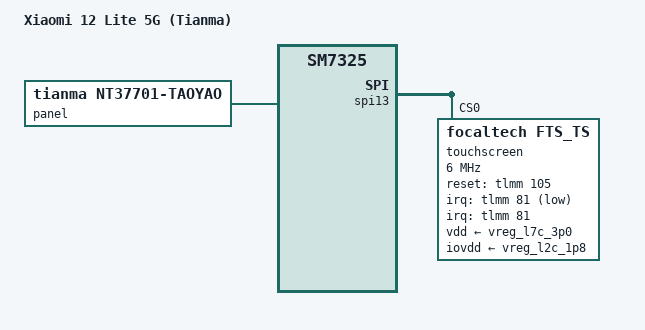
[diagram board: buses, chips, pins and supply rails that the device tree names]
// SPDX-License-Identifier: (GPL-2.0+ OR BSD-3-Clause)
/*
 * Copyright (c) 2025, Stanislav Zaikin <zstaseg@gmail.com>
 */

/dts-v1/;

#include "sm7325-xiaomi-taoyao-common.dtsi"

/ {
	model = "Xiaomi 12 Lite 5G (Tianma)";
	compatible = "xiaomi,taoyao", "qcom,sm7325";
};

&panel {
	compatible = "tianma,nt37701-taoyao";
	status = "okay";
};

&spi13 {
	touchscreen@0 {
		compatible = "focaltech,fts_ts";
		reg = <0>;

		spi-max-frequency = <6000000>;

		interrupt-parent = <&tlmm>;
		interrupts = <81 IRQ_TYPE_LEVEL_LOW>;
		reset-gpios = <&tlmm 105 GPIO_ACTIVE_HIGH>;
		focaltech,irq-gpios = <&tlmm 81 GPIO_ACTIVE_LOW>;
		focaltech,display-coords = <0 0 1080 2400>;
		focaltech,max-touch-number = <10>;

		vdd-supply = <&vreg_l7c_3p0>;
		iovdd-supply = <&vreg_l2c_1p8>;

		pinctrl-0 = <&ts_irq>, <&ts_reset>;
		pinctrl-names = "default";
	};
};
